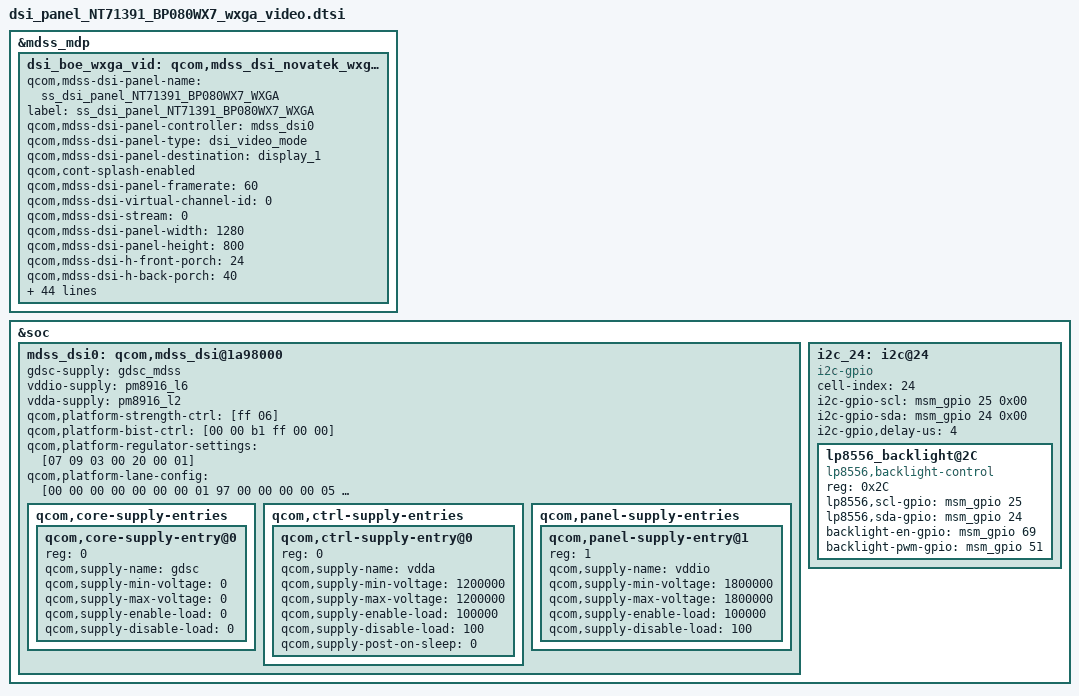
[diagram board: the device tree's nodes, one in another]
/* Copyright (c) 2013, The Linux Foundation. All rights reserved.
 *
 * This program is free software; you can redistribute it and/or modify
 * it under the terms of the GNU General Public License version 2 and
 * only version 2 as published by the Free Software Foundation.
 *
 * This program is distributed in the hope that it will be useful,
 * but WITHOUT ANY WARRANTY; without even the implied warranty of
 * MERCHANTABILITY or FITNESS FOR A PARTICULAR PURPOSE.  See the
 * GNU General Public License for more details.
 */

/*---------------------------------------------------------------------------
 * This file is autogenerated file using gcdb parser. Please do not edit it.
 * Update input XML file to add a new entry or update variable in this file
 * VERSION = "1.0"
 *---------------------------------------------------------------------------*/
&mdss_mdp {
	dsi_boe_wxga_vid: qcom,mdss_dsi_novatek_wxga_video {
		qcom,mdss-dsi-panel-name = "ss_dsi_panel_NT71391_BP080WX7_WXGA";
		label = "ss_dsi_panel_NT71391_BP080WX7_WXGA";
		qcom,mdss-dsi-panel-controller = <&mdss_dsi0>;
		qcom,mdss-dsi-panel-type = "dsi_video_mode";
		qcom,mdss-dsi-panel-destination = "display_1";
		qcom,cont-splash-enabled;
		qcom,mdss-dsi-panel-framerate = <60>;
		qcom,mdss-dsi-virtual-channel-id = <0>;
		qcom,mdss-dsi-stream = <0>;
		qcom,mdss-dsi-panel-width = <1280>;
		qcom,mdss-dsi-panel-height = <800>;
		qcom,mdss-dsi-h-front-porch = <24>;
		qcom,mdss-dsi-h-back-porch = <40>;
		qcom,mdss-dsi-h-pulse-width = <16>;
		qcom,mdss-dsi-h-sync-skew = <0>;
		qcom,mdss-dsi-v-back-porch = <3>;
		qcom,mdss-dsi-v-front-porch = <14>;
		qcom,mdss-dsi-v-pulse-width = <6>;
		qcom,mdss-dsi-h-left-border = <0>;
		qcom,mdss-dsi-h-right-border = <0>;
		qcom,mdss-dsi-v-top-border = <0>;
		qcom,mdss-dsi-v-bottom-border = <0>;
		qcom,mdss-dsi-bpp = <24>;
		qcom,mdss-dsi-underflow-color = <0xff>;
		qcom,mdss-dsi-border-color = <0>;
		qcom,mdss-dsi-on-command = [
			39 01 00 00 0A 00 02 32 00
		];
		qcom,mdss-dsi-off-command = [
		];
		qcom,mdss-dsi-on-command-state = "dsi_lp_mode";
		qcom,mdss-dsi-off-command-state = "dsi_hs_mode";
		qcom,mdss-dsi-h-sync-pulse = <0>;
		qcom,mdss-dsi-traffic-mode = "burst_mode";
		qcom,mdss-dsi-bllp-eof-power-mode;
		qcom,mdss-dsi-bllp-power-mode;
		qcom,mdss-dsi-lane-0-state;
		qcom,mdss-dsi-lane-1-state;
		qcom,mdss-dsi-lane-2-state;
		qcom,mdss-dsi-lane-3-state;
		qcom,mdss-dsi-panel-timings = [66 2B 0D 00 37 3D 12 2F 17 03 04 00];
		qcom,mdss-dsi-t-clk-post = <0x04>;
		qcom,mdss-dsi-t-clk-pre = <0x16>;
		qcom,mdss-dsi-bl-min-level = <1>;
		qcom,mdss-dsi-bl-max-level = <255>;
		qcom,mdss-dsi-dma-trigger = "trigger_sw";
		qcom,mdss-dsi-mdp-trigger = "none";
		qcom,mdss-dsi-bl-pmic-control-type = "bl_ctrl_ss_pwm";
		samsung,tft-common-support;
		samsung,backlight-gpio-config;
		samsung,backlight-pwm-ap-support;
		qcom,mdss-dsi-reset-sequence = <0 20>, <1 100>;
		qcom,mdss-pan-physical-width-dimension = <172>;
		qcom,mdss-pan-physical-height-dimension = <108>;
		qcom,mdss-dsi-lp11-init;
		qcom,mdss-dsi-init-delay-us = <20000>;
		qcom,mdss-force-clk-lane-hs = <1>;
	};
};
&soc {
	mdss_dsi0: qcom,mdss_dsi@1a98000 {
		gdsc-supply = <&gdsc_mdss>;
		vddio-supply = <&pm8916_l6>;
		vdda-supply = <&pm8916_l2>;
		qcom,platform-strength-ctrl = [ff 06];
		qcom,platform-bist-ctrl = [00 00 b1 ff 00 00];
		qcom,platform-regulator-settings = [07 09 03 00 20 00 01];
		qcom,platform-lane-config = [00 00 00 00 00 00 00 01 97
			00 00 00 00 05 00 00 01 97
			00 00 00 00 0a 00 00 01 97
			00 00 00 00 0f 00 00 01 97
			00 c0 00 00 00 00 00 01 bb];
		qcom,core-supply-entries {
			#address-cells = <1>;
			#size-cells = <0>;

			qcom,core-supply-entry@0 {
				reg = <0>;
				qcom,supply-name = "gdsc";
				qcom,supply-min-voltage = <0>;
				qcom,supply-max-voltage = <0>;
				qcom,supply-enable-load = <0>;
				qcom,supply-disable-load = <0>;
			};
		};
		qcom,ctrl-supply-entries {
			#address-cells = <1>;
			#size-cells = <0>;

			qcom,ctrl-supply-entry@0 {
				reg = <0>;
				qcom,supply-name = "vdda";
				qcom,supply-min-voltage = <1200000>;
				qcom,supply-max-voltage = <1200000>;
				qcom,supply-enable-load = <100000>;
				qcom,supply-disable-load = <100>;
				qcom,supply-post-on-sleep = <0>;
			};
		};
		qcom,panel-supply-entries {
			#address-cells = <1>;
			#size-cells = <0>;

			qcom,panel-supply-entry@1 {
				reg = <1>;
				qcom,supply-name = "vddio";
				qcom,supply-min-voltage = <1800000>;
				qcom,supply-max-voltage = <1800000>;
				qcom,supply-enable-load = <100000>;
				qcom,supply-disable-load = <100>;
			};
		};
	};
	i2c_24: i2c@24 {

		cell-index = <24>;
		compatible = "i2c-gpio";
		i2c-gpio-scl = <&msm_gpio 25  0x00>; /*scl gpio*/
		i2c-gpio-sda = <&msm_gpio 24 0x00>;  /*sda gpio*/
		i2c-gpio,delay-us = <4>;
		lp8556_backlight@2C {
			compatible = "lp8556,backlight-control";
			reg = <0x2C>;
			lp8556,scl-gpio = <&msm_gpio 25 0x00>;
			lp8556,sda-gpio = <&msm_gpio 24 0x00>;
			backlight-en-gpio = <&msm_gpio 69 0x00>;
			backlight-pwm-gpio = <&msm_gpio 51 0x00>;
		};
	};
};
